AUTOSAR XML (schema 00044)
package /E40_Platform_System_SystemPackage/Components
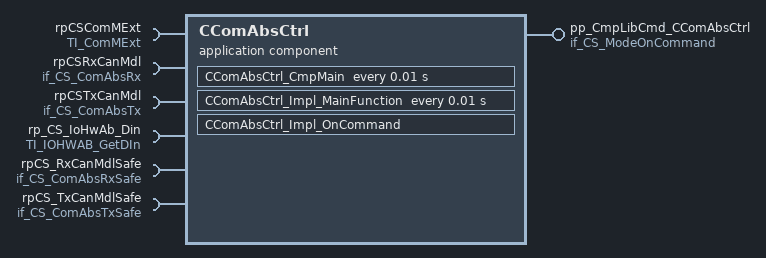
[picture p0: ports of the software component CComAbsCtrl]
  application sw component type CComAbsCtrl
    provide port pp_CmpLibCmd_CComAbsCtrl: server-com-spec{operation=Impl_OnCommand, queue-length=1}, provided-interface=if_CS_ModeOnCommand
    6 x require port:
      rpCSComMExt: required-interface=TI_ComMExt
        required-com-specs:
          CAN_ActivateSilentCommunication
          CAN_CommControlActivateRx
          CAN_CommControlActivateTx
          CAN_CommControlDeActivateRx
          CAN_CommControlDeActivateTx
          CAN_CommControlSetDone
          CAN_DeActivateSilentCommunication
          CAN_GetCurrentComMode
          CAN_ReleaseCommunication
          CAN_RequestCommunication
          GetBusOffStatus
          Get_MCAN_ERR_PIN_Status
          Init
      rpCSRxCanMdl: required-interface=if_CS_ComAbsRx
        required-com-specs:
          RxCan_GetSignalValue
          RxCan_GetSignalValueU8Arr
          RxCan_SetSignalInitValue
          RxCan_SetSignalInitValueU8Arr
          RxCan_SignalClearJustRcvdStatus
          RxCan_SignalGetJustRcvdStatus
          RxCan_SignalInvalidProcessingControl
          RxCan_SignalMissingProcessingControl
          RxCan_SignalNRProcessingControl
      rpCSTxCanMdl: required-interface=if_CS_ComAbsTx
        required-com-specs:
          TxCan_ClearCanSignalTxConfirmation
          TxCan_GetCanSignalTxConfirmation
          TxCan_SetSignalFromRetentionBuffer
          TxCan_SetSignalValue
          TxCan_SetSignalValueU8Arr
      rp_CS_IoHwAb_Din: required-com-specs=[GetAsyncRawInput, GetInputGroup, GetProcessedInput, GetSyncRawInput], required-interface=TI_IOHWAB_GetDIn
      rpCS_RxCanMdlSafe: required-interface=if_CS_ComAbsRxSafe
        required-com-specs:
          RxCan_GetSignalValue
          RxCan_GetSignalValueU8Arr
          RxCan_SetSignalInitValue
          RxCan_SetSignalInitValueU8Arr
          RxCan_SignalClearJustRcvdStatus
          RxCan_SignalGetJustRcvdStatus
          RxCan_SignalInvalidProcessingControl
          RxCan_SignalMissingProcessingControl
          RxCan_SignalNRProcessingControl
      rpCS_TxCanMdlSafe: required-interface=if_CS_ComAbsTxSafe
        required-com-specs:
          TxCan_ClearCanSignalTxConfirmation
          TxCan_GetCanSignalTxConfirmation
          TxCan_SetSignalFromRetentionBuffer
          TxCan_SetSignalValue
          TxCan_SetSignalValueU8Arr
    behavior IB_CComAbsCtrl
      timing event TECComAbsCtrl_CmpMain: start-on-event=CComAbsCtrl_CmpMain, period=0.01
      timing event TECComAbsCtrl_Impl_MainFunction: start-on-event=CComAbsCtrl_Impl_MainFunction, period=0.01
      operation invoked event OIE_pp_CmpLibCmd_CComAbsCtrl_CComAbsCtrl_Impl_OnCommandTrigByImpl_OnCommand: start-on-event=CComAbsCtrl_Impl_OnCommand, operation=pp_CmpLibCmd_CComAbsCtrl.Impl_OnCommand
      port-api-options:
        enable-take-address=false, indirect-api=false, port=pp_CmpLibCmd_CComAbsCtrl
        enable-take-address=false, indirect-api=false, port=rpCSComMExt
        enable-take-address=false, indirect-api=false, port=rpCSRxCanMdl
        enable-take-address=false, indirect-api=false, port=rpCSTxCanMdl
        enable-take-address=false, indirect-api=false, port=rp_CS_IoHwAb_Din
        enable-take-address=false, indirect-api=false, port=rpCS_RxCanMdlSafe
        enable-take-address=false, indirect-api=false, port=rpCS_TxCanMdlSafe
      runnable CComAbsCtrl_CmpMain: can-be-invoked-concurrently=true
      runnable CComAbsCtrl_Impl_MainFunction: can-be-invoked-concurrently=true
        45 x sync call:
          OA_rpCSComMExt_Get_MCAN_ERR_PIN_Status: operation=rpCSComMExt.Get_MCAN_ERR_PIN_Status
          OA_rpCSComMExt_Init: operation=rpCSComMExt.Init
          OA_rpCSComMExt_GetBusOffStatus: operation=rpCSComMExt.GetBusOffStatus
          OA_rpCSComMExt_CAN_RequestCommunication: operation=rpCSComMExt.CAN_RequestCommunication
          OA_rpCSComMExt_CAN_GetCurrentComMode: operation=rpCSComMExt.CAN_GetCurrentComMode
          OA_rpCSComMExt_CAN_ReleaseCommunication: operation=rpCSComMExt.CAN_ReleaseCommunication
          OA_rpCSComMExt_CAN_DeActivateSilentCommunication: operation=rpCSComMExt.CAN_DeActivateSilentCommunication
          OA_rpCSComMExt_CAN_CommControlSetDone: operation=rpCSComMExt.CAN_CommControlSetDone
          OA_rpCSComMExt_CAN_CommControlDeActivateTx: operation=rpCSComMExt.CAN_CommControlDeActivateTx
          OA_rpCSComMExt_CAN_CommControlDeActivateRx: operation=rpCSComMExt.CAN_CommControlDeActivateRx
          OA_rpCSComMExt_CAN_ActivateSilentCommunication: operation=rpCSComMExt.CAN_ActivateSilentCommunication
          OA_rpCSComMExt_CAN_CommControlActivateRx: operation=rpCSComMExt.CAN_CommControlActivateRx
          OA_rpCSComMExt_CAN_CommControlActivateTx: operation=rpCSComMExt.CAN_CommControlActivateTx
          OA_rpCSRxCanMdl_RxCan_GetSignalValueU8Arr: operation=rpCSRxCanMdl.RxCan_GetSignalValueU8Arr
          OA_rpCSRxCanMdl_RxCan_SetSignalInitValue: operation=rpCSRxCanMdl.RxCan_SetSignalInitValue
          OA_rpCSRxCanMdl_RxCan_SetSignalInitValueU8Arr: operation=rpCSRxCanMdl.RxCan_SetSignalInitValueU8Arr
          OA_rpCSRxCanMdl_RxCan_SignalInvalidProcessingControl: operation=rpCSRxCanMdl.RxCan_SignalInvalidProcessingControl
          OA_rpCSRxCanMdl_RxCan_SignalMissingProcessingControl: operation=rpCSRxCanMdl.RxCan_SignalMissingProcessingControl
          OA_rpCSRxCanMdl_RxCan_SignalNRProcessingControl: operation=rpCSRxCanMdl.RxCan_SignalNRProcessingControl
          OA_rpCSRxCanMdl_RxCan_SignalGetJustRcvdStatus: operation=rpCSRxCanMdl.RxCan_SignalGetJustRcvdStatus
          OA_rpCSRxCanMdl_RxCan_SignalClearJustRcvdStatus: operation=rpCSRxCanMdl.RxCan_SignalClearJustRcvdStatus
          OA_rpCSRxCanMdl_RxCan_GetSignalValue: operation=rpCSRxCanMdl.RxCan_GetSignalValue
          OA_rpCSTxCanMdl_TxCan_ClearCanSignalTxConfirmation: operation=rpCSTxCanMdl.TxCan_ClearCanSignalTxConfirmation
          OA_rpCSTxCanMdl_TxCan_GetCanSignalTxConfirmation: operation=rpCSTxCanMdl.TxCan_GetCanSignalTxConfirmation
          OA_rpCSTxCanMdl_TxCan_SetSignalFromRetentionBuffer: operation=rpCSTxCanMdl.TxCan_SetSignalFromRetentionBuffer
          OA_rpCSTxCanMdl_TxCan_SetSignalValue: operation=rpCSTxCanMdl.TxCan_SetSignalValue
          OA_rpCSTxCanMdl_TxCan_SetSignalValueU8Arr: operation=rpCSTxCanMdl.TxCan_SetSignalValueU8Arr
          OA_rp_CS_IoHwAb_Din_GetAsyncRawInput: operation=rp_CS_IoHwAb_Din.GetAsyncRawInput
          OA_rp_CS_IoHwAb_Din_GetProcessedInput: operation=rp_CS_IoHwAb_Din.GetProcessedInput
          OA_rp_CS_IoHwAb_Din_GetSyncRawInput: operation=rp_CS_IoHwAb_Din.GetSyncRawInput
          OA_rp_CS_IoHwAb_Din_GetInputGroup: operation=rp_CS_IoHwAb_Din.GetInputGroup
          OA_rpCS_RxCanMdlSafe_RxCan_GetSignalValueU8Arr: operation=rpCS_RxCanMdlSafe.RxCan_GetSignalValueU8Arr
          OA_rpCS_RxCanMdlSafe_RxCan_SetSignalInitValue: operation=rpCS_RxCanMdlSafe.RxCan_SetSignalInitValue
          OA_rpCS_RxCanMdlSafe_RxCan_SetSignalInitValueU8Arr: operation=rpCS_RxCanMdlSafe.RxCan_SetSignalInitValueU8Arr
          OA_rpCS_RxCanMdlSafe_RxCan_SignalInvalidProcessingControl: operation=rpCS_RxCanMdlSafe.RxCan_SignalInvalidProcessingControl
          OA_rpCS_RxCanMdlSafe_RxCan_SignalMissingProcessingControl: operation=rpCS_RxCanMdlSafe.RxCan_SignalMissingProcessingControl
          OA_rpCS_RxCanMdlSafe_RxCan_SignalNRProcessingControl: operation=rpCS_RxCanMdlSafe.RxCan_SignalNRProcessingControl
          OA_rpCS_RxCanMdlSafe_RxCan_SignalGetJustRcvdStatus: operation=rpCS_RxCanMdlSafe.RxCan_SignalGetJustRcvdStatus
          OA_rpCS_RxCanMdlSafe_RxCan_SignalClearJustRcvdStatus: operation=rpCS_RxCanMdlSafe.RxCan_SignalClearJustRcvdStatus
          OA_rpCS_RxCanMdlSafe_RxCan_GetSignalValue: operation=rpCS_RxCanMdlSafe.RxCan_GetSignalValue
          OA_rpCS_TxCanMdlSafe_TxCan_ClearCanSignalTxConfirmation: operation=rpCS_TxCanMdlSafe.TxCan_ClearCanSignalTxConfirmation
          OA_rpCS_TxCanMdlSafe_TxCan_GetCanSignalTxConfirmation: operation=rpCS_TxCanMdlSafe.TxCan_GetCanSignalTxConfirmation
          OA_rpCS_TxCanMdlSafe_TxCan_SetSignalFromRetentionBuffer: operation=rpCS_TxCanMdlSafe.TxCan_SetSignalFromRetentionBuffer
          OA_rpCS_TxCanMdlSafe_TxCan_SetSignalValue: operation=rpCS_TxCanMdlSafe.TxCan_SetSignalValue
          OA_rpCS_TxCanMdlSafe_TxCan_SetSignalValueU8Arr: operation=rpCS_TxCanMdlSafe.TxCan_SetSignalValueU8Arr
      runnable CComAbsCtrl_Impl_OnCommand: can-be-invoked-concurrently=true
  swc implementation IMPL_CComAbsCtrl: behavior=IB_CComAbsCtrl
